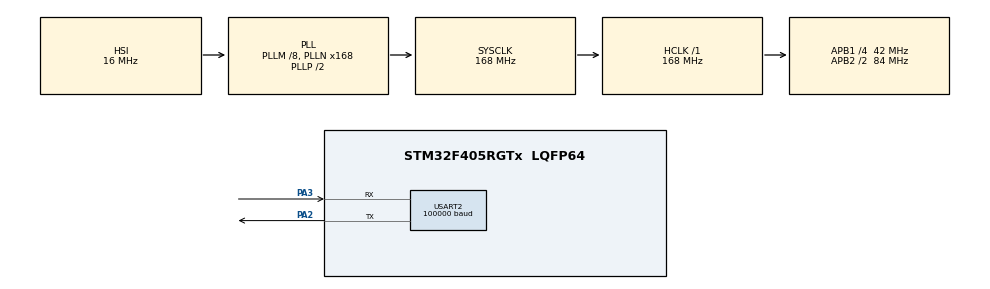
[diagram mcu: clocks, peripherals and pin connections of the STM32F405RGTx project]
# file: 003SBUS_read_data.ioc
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Mcu.Family=STM32F4
Mcu.Name=STM32F405RGTx
Mcu.Package=LQFP64
NVIC.PriorityGroup=NVIC_PRIORITYGROUP_4
NVIC.USART2_IRQn=true\:1\:0\:true\:false\:true\:true\:true\:true
PA13.Mode=Serial_Wire
PA13.Signal=SYS_JTMS-SWDIO
PA14.Mode=Serial_Wire
PA14.Signal=SYS_JTCK-SWCLK
PA2.Mode=Asynchronous
PA2.Signal=USART2_TX
PA3.Mode=Asynchronous
PA3.Signal=USART2_RX
PC14-OSC32_IN.Mode=LSE-External-Oscillator
PC14-OSC32_IN.Signal=RCC_OSC32_IN
PC15-OSC32_OUT.Mode=LSE-External-Oscillator
PC15-OSC32_OUT.Signal=RCC_OSC32_OUT
PH0-OSC_IN.Mode=HSE-External-Oscillator
PH0-OSC_IN.Signal=RCC_OSC_IN
PH1-OSC_OUT.Mode=HSE-External-Oscillator
PH1-OSC_OUT.Signal=RCC_OSC_OUT
ProjectManager.HeapSize=0x200
ProjectManager.StackSize=0x400
ProjectManager.TargetToolchain=STM32CubeIDE
RCC.48MHZClocksFreq_Value=84000000
RCC.AHBFreq_Value=168000000
RCC.APB1CLKDivider=RCC_HCLK_DIV4
RCC.APB1Freq_Value=42000000
RCC.APB1TimFreq_Value=84000000
RCC.APB2CLKDivider=RCC_HCLK_DIV2
RCC.APB2Freq_Value=84000000
RCC.APB2TimFreq_Value=168000000
RCC.CortexFreq_Value=168000000
RCC.HCLKFreq_Value=168000000
RCC.HSE_VALUE=25000000
RCC.HSI_VALUE=16000000
RCC.PLLM=8
RCC.PLLN=168
RCC.SYSCLKFreq_VALUE=168000000
RCC.SYSCLKSource=RCC_SYSCLKSOURCE_PLLCLK
RCC.VCOOutputFreq_Value=336000000
USART2.BaudRate=100000
USART2.Parity=PARITY_EVEN
USART2.StopBits=STOPBITS_2
USART2.VirtualMode=VM_ASYNC
USART2.WordLength=WORDLENGTH_9B
board=custom

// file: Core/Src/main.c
/* USER CODE BEGIN Header */
/**
  ******************************************************************************
  * @file           : main.c
  * @brief          : Main program body
  ******************************************************************************
  * @attention
  *
  * Copyright (c) 2026 STMicroelectronics.
  * All rights reserved.
  *
  * This software is licensed under terms that can be found in the LICENSE file
  * in the root directory of this software component.
  * If no LICENSE file comes with this software, it is provided AS-IS.
  *
  ******************************************************************************
  */
/* USER CODE END Header */
#include "main.h"

UART_HandleTypeDef huart2;

/* USER CODE BEGIN PV */
uint8_t sbusRx[25];
uint16_t channel[16];
/* USER CODE END PV */

void SystemClock_Config(void);
static void MX_GPIO_Init(void);
static void MX_USART2_UART_Init(void);
/* USER CODE BEGIN PFP */
void SBUS_Decode(uint8_t *buf, uint16_t *ch)
{
    ch[0]  = ((buf[1]      | buf[2]  << 8)                         & 0x07FF);
    ch[1]  = ((buf[2] >> 3 | buf[3]  << 5)                         & 0x07FF);
    ch[2]  = ((buf[3] >> 6 | buf[4]  << 2 | buf[5]  << 10)         & 0x07FF);
    ch[3]  = ((buf[5] >> 1 | buf[6]  << 7)                         & 0x07FF);
    ch[4]  = ((buf[6] >> 4 | buf[7]  << 4)                         & 0x07FF);
    ch[5]  = ((buf[7] >> 7 | buf[8]  << 1 | buf[9]  << 9)          & 0x07FF);
    ch[6]  = ((buf[9] >> 2 | buf[10] << 6)                         & 0x07FF);
    ch[7]  = ((buf[10]>>5 | buf[11] <<3)                           & 0x07FF);

    ch[8]  = ((buf[12]     | buf[13] <<8)                          & 0x07FF);
    ch[9]  = ((buf[13]>>3  | buf[14] <<5)                          & 0x07FF);
    ch[10] = ((buf[14]>>6  | buf[15] <<2 | buf[16]<<10)            & 0x07FF);
    ch[11] = ((buf[16]>>1  | buf[17] <<7)                          & 0x07FF);
    ch[12] = ((buf[17]>>4  | buf[18] <<4)                          & 0x07FF);
    ch[13] = ((buf[18]>>7  | buf[19] <<1 | buf[20]<<9)             & 0x07FF);
    ch[14] = ((buf[20]>>2  | buf[21] <<6)                          & 0x07FF);
    ch[15] = ((buf[21]>>5  | buf[22] <<3)                          & 0x07FF);
}
/* USER CODE END PFP */

int main(void)
{

  /* MCU Configuration--------------------------------------------------------*/

  /* Reset of all peripherals, Initializes the Flash interface and the Systick. */
  HAL_Init();

  /* Configure the system clock */
  SystemClock_Config();

  /* Initialize all configured peripherals */
  MX_GPIO_Init();
  MX_USART2_UART_Init();
  /* USER CODE BEGIN 2 */
  HAL_UART_Receive_IT(&huart2, sbusRx, 25);
  /* USER CODE END 2 */

  /* Infinite loop */
  while (1)
  {

  }
}

void SystemClock_Config(void)
{
  RCC_OscInitTypeDef RCC_OscInitStruct = {0};
  RCC_ClkInitTypeDef RCC_ClkInitStruct = {0};

  /** Configure the main internal regulator output voltage
  */
  __HAL_RCC_PWR_CLK_ENABLE();
  __HAL_PWR_VOLTAGESCALING_CONFIG(PWR_REGULATOR_VOLTAGE_SCALE1);

  /** Initializes the RCC Oscillators according to the specified parameters
  * in the RCC_OscInitTypeDef structure.
  */
  RCC_OscInitStruct.OscillatorType = RCC_OSCILLATORTYPE_HSI;
  RCC_OscInitStruct.HSIState = RCC_HSI_ON;
  RCC_OscInitStruct.HSICalibrationValue = RCC_HSICALIBRATION_DEFAULT;
  RCC_OscInitStruct.PLL.PLLState = RCC_PLL_ON;
  RCC_OscInitStruct.PLL.PLLSource = RCC_PLLSOURCE_HSI;
  RCC_OscInitStruct.PLL.PLLM = 8;
  RCC_OscInitStruct.PLL.PLLN = 168;
  RCC_OscInitStruct.PLL.PLLP = RCC_PLLP_DIV2;
  RCC_OscInitStruct.PLL.PLLQ = 4;
  if (HAL_RCC_OscConfig(&RCC_OscInitStruct) != HAL_OK)
  {
    Error_Handler();
  }

  /** Initializes the CPU, AHB and APB buses clocks
  */
  RCC_ClkInitStruct.ClockType = RCC_CLOCKTYPE_HCLK|RCC_CLOCKTYPE_SYSCLK
                              |RCC_CLOCKTYPE_PCLK1|RCC_CLOCKTYPE_PCLK2;
  RCC_ClkInitStruct.SYSCLKSource = RCC_SYSCLKSOURCE_PLLCLK;
  RCC_ClkInitStruct.AHBCLKDivider = RCC_SYSCLK_DIV1;
  RCC_ClkInitStruct.APB1CLKDivider = RCC_HCLK_DIV4;
  RCC_ClkInitStruct.APB2CLKDivider = RCC_HCLK_DIV2;

  if (HAL_RCC_ClockConfig(&RCC_ClkInitStruct, FLASH_LATENCY_5) != HAL_OK)
  {
    Error_Handler();
  }
}

static void MX_USART2_UART_Init(void)
{

  huart2.Instance = USART2;
  huart2.Init.BaudRate = 100000;
  huart2.Init.WordLength = UART_WORDLENGTH_9B;
  huart2.Init.StopBits = UART_STOPBITS_2;
  huart2.Init.Parity = UART_PARITY_EVEN;
  huart2.Init.Mode = UART_MODE_TX_RX;
  huart2.Init.HwFlowCtl = UART_HWCONTROL_NONE;
  huart2.Init.OverSampling = UART_OVERSAMPLING_16;
  if (HAL_UART_Init(&huart2) != HAL_OK)
  {
    Error_Handler();
  }

}

static void MX_GPIO_Init(void)
{

  /* GPIO Ports Clock Enable */
  __HAL_RCC_GPIOC_CLK_ENABLE();
  __HAL_RCC_GPIOH_CLK_ENABLE();
  __HAL_RCC_GPIOA_CLK_ENABLE();

}

/* USER CODE BEGIN 4 */
void HAL_UART_RxCpltCallback(UART_HandleTypeDef *huart)
{
    if(huart->Instance == USART2)
    {
        if(sbusRx[0] == 0x0F && sbusRx[24] == 0x00)
        {
            SBUS_Decode(sbusRx, channel);
        }

        HAL_UART_Receive_IT(&huart2, sbusRx, 25);
    }
}
/* USER CODE END 4 */

void Error_Handler(void)
{
  __disable_irq();
  while (1)
  {
  }
}
